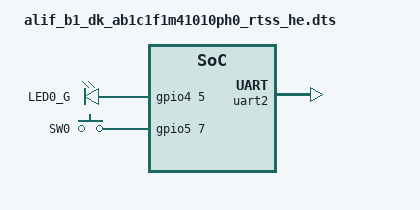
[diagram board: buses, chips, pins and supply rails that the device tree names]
/* Copyright (c) 2026 Alif Semiconductor
 *
 * SPDX-License-Identifier: Apache-2.0
 */

/dts-v1/;

#include <alif/balletto/b1/ab1c1f1m41010ph0.dtsi>
#include "../common/balletto-pinctrl.dtsi"

/ {
	compatible = "arm,alif-b1-dk-ab1c1f1m41010ph0-rtss-he";
	#address-cells = <1>;
	#size-cells = <1>;
};

&{/} {
	chosen {
		zephyr,console = &uart2;
		zephyr,shell-uart = &uart2;
	};

	aliases {
		led0 = &aled0;
		sw0 = &button0;
		watchdog0 = &wdog0;
	};

	leds {
		compatible = "gpio-leds";
		aled0: led_0 {
			gpios = <&gpio4 5 0>;
			label = "LED0_G";
		};
	};

	buttons {
		compatible = "gpio-keys";
		button0: button_0 {
			gpios = <&gpio5 7 0>;
			label = "SW0";
		};
	};
};

&uart2 {
	status = "okay";
};

&gpio4 {
	status = "okay";
};
